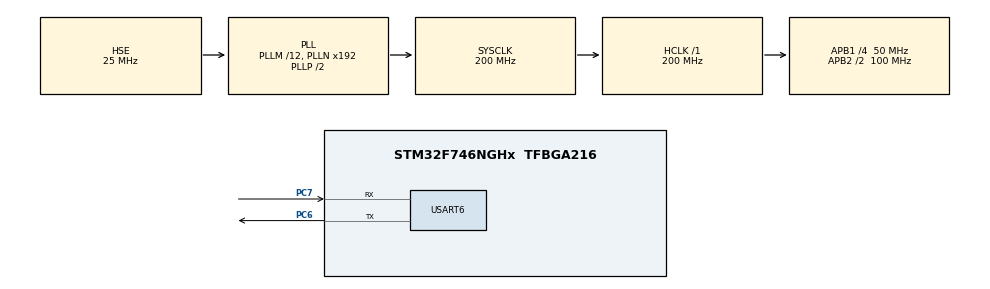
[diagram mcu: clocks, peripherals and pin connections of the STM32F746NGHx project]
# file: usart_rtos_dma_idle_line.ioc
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Dma.Request0=USART6_RX
Dma.Request1=USART6_TX
Dma.USART6_RX.0.Direction=DMA_PERIPH_TO_MEMORY
Dma.USART6_RX.0.FIFOMode=DMA_FIFOMODE_DISABLE
Dma.USART6_RX.0.Instance=DMA2_Stream1
Dma.USART6_RX.0.MemDataAlignment=DMA_MDATAALIGN_BYTE
Dma.USART6_RX.0.MemInc=DMA_MINC_ENABLE
Dma.USART6_RX.0.Mode=DMA_CIRCULAR
Dma.USART6_RX.0.PeriphDataAlignment=DMA_PDATAALIGN_BYTE
Dma.USART6_RX.0.PeriphInc=DMA_PINC_DISABLE
Dma.USART6_RX.0.Priority=DMA_PRIORITY_LOW
Dma.USART6_TX.1.Direction=DMA_MEMORY_TO_PERIPH
Dma.USART6_TX.1.FIFOMode=DMA_FIFOMODE_DISABLE
Dma.USART6_TX.1.Instance=DMA2_Stream6
Dma.USART6_TX.1.MemDataAlignment=DMA_MDATAALIGN_BYTE
Dma.USART6_TX.1.MemInc=DMA_MINC_ENABLE
Dma.USART6_TX.1.Mode=DMA_NORMAL
Dma.USART6_TX.1.PeriphDataAlignment=DMA_PDATAALIGN_BYTE
Dma.USART6_TX.1.PeriphInc=DMA_PINC_DISABLE
Dma.USART6_TX.1.Priority=DMA_PRIORITY_LOW
FREERTOS.Tasks01=usartTask,24,1024,usartTaskFunc,Default,NULL,Dynamic,NULL,NULL;txTask,8,1024,txTaskFunc,Default,NULL,Dynamic,NULL,NULL
FREERTOS.configTOTAL_HEAP_SIZE=65536
Mcu.Family=STM32F7
Mcu.Name=STM32F746NGHx
Mcu.Package=TFBGA216
NVIC.DMA2_Stream1_IRQn=true\:5\:0\:false\:false\:true\:true\:false\:true
NVIC.DMA2_Stream6_IRQn=true\:5\:0\:false\:false\:true\:true\:false\:true
NVIC.PriorityGroup=NVIC_PRIORITYGROUP_4
NVIC.TIM6_DAC_IRQn=true\:0\:0\:false\:false\:true\:false\:false\:true
NVIC.TimeBase=TIM6_DAC_IRQn
NVIC.TimeBaseIP=TIM6
NVIC.USART6_IRQn=true\:5\:0\:false\:false\:true\:true\:true\:true
PA13.Mode=Serial_Wire
PA13.Signal=SYS_JTMS-SWDIO
PA14.Mode=Serial_Wire
PA14.Signal=SYS_JTCK-SWCLK
PC14/OSC32_IN.Mode=LSE-External-Oscillator
PC14/OSC32_IN.Signal=RCC_OSC32_IN
PC15/OSC32_OUT.Mode=LSE-External-Oscillator
PC15/OSC32_OUT.Signal=RCC_OSC32_OUT
PC6.Mode=Asynchronous
PC6.Signal=USART6_TX
PC7.Mode=Asynchronous
PC7.Signal=USART6_RX
PH0/OSC_IN.Mode=HSE-External-Oscillator
PH0/OSC_IN.Signal=RCC_OSC_IN
PH1/OSC_OUT.Mode=HSE-External-Oscillator
PH1/OSC_OUT.Signal=RCC_OSC_OUT
ProjectManager.HeapSize=0x200
ProjectManager.StackSize=0x400
ProjectManager.TargetToolchain=STM32CubeIDE
RCC.AHBFreq_Value=200000000
RCC.APB1CLKDivider=RCC_HCLK_DIV4
RCC.APB1Freq_Value=50000000
RCC.APB1TimFreq_Value=100000000
RCC.APB2CLKDivider=RCC_HCLK_DIV2
RCC.APB2Freq_Value=100000000
RCC.APB2TimFreq_Value=200000000
RCC.CortexFreq_Value=200000000
RCC.HCLKFreq_Value=200000000
RCC.HSE_VALUE=25000000
RCC.HSI_VALUE=16000000
RCC.PLLM=12
RCC.PLLSourceVirtual=RCC_PLLSOURCE_HSE
RCC.SYSCLKFreq_VALUE=200000000
RCC.SYSCLKSource=RCC_SYSCLKSOURCE_PLLCLK
RCC.USBFreq_Value=200000000
RCC.VCOOutputFreq_Value=400000000
USART6.VirtualMode-Asynchronous=VM_ASYNC
VP_FREERTOS_VS_CMSIS_V2.Mode=CMSIS_V2
VP_SYS_VS_tim6.Mode=TIM6
board=custom

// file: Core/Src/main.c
/* USER CODE BEGIN Header */
/**
  ******************************************************************************
  * @file           : main.c
  * @brief          : Main program body
  ******************************************************************************
  * @attention
  *
  * <h2><center>&copy; Copyright (c) 2021 STMicroelectronics.
  * All rights reserved.</center></h2>
  *
  * This software component is licensed by ST under BSD 3-Clause license,
  * the "License"; You may not use this file except in compliance with the
  * License. You may obtain a copy of the License at:
  *                        opensource.org/licenses/BSD-3-Clause
  *
  ******************************************************************************
  */
/* USER CODE END Header */
#include "main.h"
#include "cmsis_os.h"
#include "dma.h"
#include "usart.h"
#include "gpio.h"

/* USER CODE BEGIN Includes */
#include <string.h>
/* USER CODE END Includes */

void SystemClock_Config(void);
void MX_FREERTOS_Init(void);

int main(void)
{

  /* MCU Configuration--------------------------------------------------------*/

  /* Reset of all peripherals, Initializes the Flash interface and the Systick. */
  HAL_Init();

  /* Configure the system clock */
  SystemClock_Config();

  /* Initialize all configured peripherals */
  MX_GPIO_Init();
  MX_DMA_Init();
  MX_USART6_UART_Init();

  /* Init scheduler */
  osKernelInitialize();  /* Call init function for freertos objects (in freertos.c) */
  MX_FREERTOS_Init();
  /* Start scheduler */
  osKernelStart();

  /* We should never get here as control is now taken by the scheduler */
  /* Infinite loop */
  while (1)
  {

  }
}

void SystemClock_Config(void)
{
  RCC_OscInitTypeDef RCC_OscInitStruct = {0};
  RCC_ClkInitTypeDef RCC_ClkInitStruct = {0};
  RCC_PeriphCLKInitTypeDef PeriphClkInitStruct = {0};

  /** Configure LSE Drive Capability
  */
  HAL_PWR_EnableBkUpAccess();
  /** Configure the main internal regulator output voltage
  */
  __HAL_RCC_PWR_CLK_ENABLE();
  __HAL_PWR_VOLTAGESCALING_CONFIG(PWR_REGULATOR_VOLTAGE_SCALE1);
  /** Initializes the RCC Oscillators according to the specified parameters
  * in the RCC_OscInitTypeDef structure.
  */
  RCC_OscInitStruct.OscillatorType = RCC_OSCILLATORTYPE_HSE;
  RCC_OscInitStruct.HSEState = RCC_HSE_ON;
  RCC_OscInitStruct.PLL.PLLState = RCC_PLL_ON;
  RCC_OscInitStruct.PLL.PLLSource = RCC_PLLSOURCE_HSE;
  RCC_OscInitStruct.PLL.PLLM = 12;
  RCC_OscInitStruct.PLL.PLLN = 192;
  RCC_OscInitStruct.PLL.PLLP = RCC_PLLP_DIV2;
  RCC_OscInitStruct.PLL.PLLQ = 2;
  if (HAL_RCC_OscConfig(&RCC_OscInitStruct) != HAL_OK)
  {
    Error_Handler();
  }
  /** Activate the Over-Drive mode
  */
  if (HAL_PWREx_EnableOverDrive() != HAL_OK)
  {
    Error_Handler();
  }
  /** Initializes the CPU, AHB and APB buses clocks
  */
  RCC_ClkInitStruct.ClockType = RCC_CLOCKTYPE_HCLK|RCC_CLOCKTYPE_SYSCLK
                              |RCC_CLOCKTYPE_PCLK1|RCC_CLOCKTYPE_PCLK2;
  RCC_ClkInitStruct.SYSCLKSource = RCC_SYSCLKSOURCE_PLLCLK;
  RCC_ClkInitStruct.AHBCLKDivider = RCC_SYSCLK_DIV1;
  RCC_ClkInitStruct.APB1CLKDivider = RCC_HCLK_DIV4;
  RCC_ClkInitStruct.APB2CLKDivider = RCC_HCLK_DIV2;

  if (HAL_RCC_ClockConfig(&RCC_ClkInitStruct, FLASH_LATENCY_6) != HAL_OK)
  {
    Error_Handler();
  }
  PeriphClkInitStruct.PeriphClockSelection = RCC_PERIPHCLK_USART6;
  PeriphClkInitStruct.Usart6ClockSelection = RCC_USART6CLKSOURCE_PCLK2;
  if (HAL_RCCEx_PeriphCLKConfig(&PeriphClkInitStruct) != HAL_OK)
  {
    Error_Handler();
  }
}

 /**
  * @brief  Period elapsed callback in non blocking mode
  * @note   This function is called  when TIM6 interrupt took place, inside
  * HAL_TIM_IRQHandler(). It makes a direct call to HAL_IncTick() to increment
  * a global variable "uwTick" used as application time base.
  * @param  htim : TIM handle
  * @retval None
  */
void HAL_TIM_PeriodElapsedCallback(TIM_HandleTypeDef *htim)
{
  if (htim->Instance == TIM6) {
    HAL_IncTick();
  }
}

void Error_Handler(void)
{
  __disable_irq();
  while (1)
  {
  }
}

/************************ (C) COPYRIGHT STMicroelectronics *****END OF FILE****/

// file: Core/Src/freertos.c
/* USER CODE BEGIN Header */
/**
  ******************************************************************************
  * File Name          : freertos.c
  * Description        : Code for freertos applications
  ******************************************************************************
  * @attention
  *
  * <h2><center>&copy; Copyright (c) 2021 STMicroelectronics.
  * All rights reserved.</center></h2>
  *
  * This software component is licensed by ST under Ultimate Liberty license
  * SLA0044, the "License"; You may not use this file except in compliance with
  * the License. You may obtain a copy of the License at:
  *                             www.st.com/SLA0044
  *
  ******************************************************************************
  */
/* USER CODE END Header */

#include "FreeRTOS.h"
#include "task.h"
#include "main.h"
#include "cmsis_os.h"

/* USER CODE BEGIN Includes */
#include "usart.h"
#include "queue.h"
#include <string.h>
#include <stdio.h>
/* USER CODE END Includes */

/* USER CODE BEGIN PTD */
typedef struct
{
	uint8_t len;
	uint8_t buf[USART_BUF_SIZE/2];
}TxPacket_t;
/* USER CODE END PTD */

/* USER CODE BEGIN Variables */
static QueueHandle_t txQueue;
/* USER CODE END Variables */
/* Definitions for usartTask */
osThreadId_t usartTaskHandle;
const osThreadAttr_t usartTask_attributes = {
  .name = "usartTask",
  .stack_size = 1024 * 4,
  .priority = (osPriority_t) osPriorityNormal,
};
/* Definitions for txTask */
osThreadId_t txTaskHandle;
const osThreadAttr_t txTask_attributes = {
  .name = "txTask",
  .stack_size = 1024 * 4,
  .priority = (osPriority_t) osPriorityLow,
};

void usartTaskFunc(void *argument);
void txTaskFunc(void *argument);

void MX_FREERTOS_Init(void); /* (MISRA C 2004 rule 8.1) */

void MX_FREERTOS_Init(void) {

  /* USER CODE BEGIN RTOS_QUEUES */
	txQueue = xQueueCreate(10, sizeof(TxPacket_t));
	if(txQueue == 0)
	{
		while(1)
		{
			;
		}
	}
  /* add queues, ... */
  /* USER CODE END RTOS_QUEUES */

  /* Create the thread(s) */
  /* creation of usartTask */
  usartTaskHandle = osThreadNew(usartTaskFunc, NULL, &usartTask_attributes);

  /* creation of txTask */
  txTaskHandle = osThreadNew(txTaskFunc, NULL, &txTask_attributes);

}

void usartTaskFunc(void *argument)
{
  /* USER CODE BEGIN usartTaskFunc */
	usartStart();
	TxPacket_t rxPacket;
  /* Infinite loop */
  for(;;)
  {
	  if(usartRecvBlocking(rxPacket.buf, &rxPacket.len))
	  {
		  // send data to task send
		  if(xQueueSend(txQueue, &rxPacket, pdMS_TO_TICKS(10)) != pdPASS)
		  {
			  Error_Handler();
		  }
	  }
  }
  /* USER CODE END usartTaskFunc */
}

void txTaskFunc(void *argument)
{
  /* USER CODE BEGIN txTaskFunc */
	TxPacket_t txpacket;
	char str[64] = {0};
  /* Infinite loop */
  for(;;)
  {
	  xQueueReceive(txQueue, &txpacket, portMAX_DELAY);
	  sprintf(str, "DMA receive len = %d\r\n", txpacket.len);
	  usartSendBlocking((uint8_t*)str, strlen(str));
	  usartSendBlocking(txpacket.buf, txpacket.len);
  }
  /* USER CODE END txTaskFunc */
}

/************************ (C) COPYRIGHT STMicroelectronics *****END OF FILE****/
